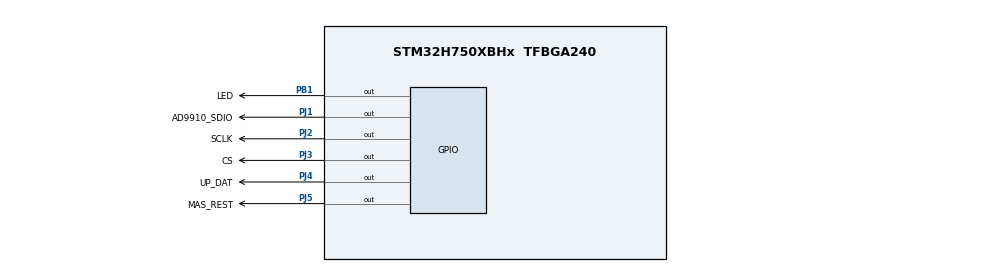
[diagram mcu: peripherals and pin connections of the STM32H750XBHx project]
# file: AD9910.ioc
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Mcu.Family=STM32H7
Mcu.Name=STM32H750XBHx
Mcu.Package=TFBGA240
NVIC.PriorityGroup=NVIC_PRIORITYGROUP_4
PB1.GPIO_Label=LED
PB1.Signal=GPIO_Output
PC14-OSC32_IN\ (OSC32_IN).Mode=LSE-External-Oscillator
PC14-OSC32_IN\ (OSC32_IN).Signal=RCC_OSC32_IN
PC15-OSC32_OUT\ (OSC32_OUT).Mode=LSE-External-Oscillator
PC15-OSC32_OUT\ (OSC32_OUT).Signal=RCC_OSC32_OUT
PH0-OSC_IN\ (PH0).Mode=HSE-External-Oscillator
PH0-OSC_IN\ (PH0).Signal=RCC_OSC_IN
PH1-OSC_OUT\ (PH1).Mode=HSE-External-Oscillator
PH1-OSC_OUT\ (PH1).Signal=RCC_OSC_OUT
PJ1.GPIO_Label=AD9910_SDIO
PJ1.Signal=GPIO_Output
PJ2.GPIO_Label=SCLK
PJ2.Signal=GPIO_Output
PJ3.GPIO_Label=CS
PJ3.Signal=GPIO_Output
PJ4.GPIO_Label=UP_DAT
PJ4.Signal=GPIO_Output
PJ5.GPIO_Label=MAS_REST
PJ5.Signal=GPIO_Output
ProjectManager.HeapSize=0x200
ProjectManager.StackSize=0x400
ProjectManager.TargetToolchain=MDK-ARM V5.32
RCC.ADCFreq_Value=50390625
RCC.APB1Freq_Value=100000000
RCC.APB2Freq_Value=100000000
RCC.APB3Freq_Value=100000000
RCC.APB4Freq_Value=100000000
RCC.CortexFreq_Value=400000000
RCC.D1PPRE=RCC_APB3_DIV2
RCC.D2PPRE1=RCC_APB1_DIV2
RCC.D2PPRE2=RCC_APB2_DIV2
RCC.D3PPRE=RCC_APB4_DIV2
RCC.DIVM1=5
RCC.DIVN1=160
RCC.HCLKFreq_Value=200000000
RCC.HPRE=RCC_HCLK_DIV2
RCC.PLLSourceVirtual=RCC_PLLSOURCE_HSE
RCC.SYSCLKFreq_VALUE=400000000
RCC.SYSCLKSource=RCC_SYSCLKSOURCE_PLLCLK
RCC.USBFreq_Value=400000000
board=custom

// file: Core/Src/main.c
/* USER CODE BEGIN Header */
/**
  ******************************************************************************
  * @file           : main.c
  * @brief          : Main program body
  ******************************************************************************
  * @attention
  *
  * Copyright (c) 2024 STMicroelectronics.
  * All rights reserved.
  *
  * This software is licensed under terms that can be found in the LICENSE file
  * in the root directory of this software component.
  * If no LICENSE file comes with this software, it is provided AS-IS.
  *
  ******************************************************************************
  */
/* USER CODE END Header */
#include "main.h"
#include "gpio.h"
#include "AD9910.h"

void SystemClock_Config(void);
static void MPU_Config(void);

int main(void)
{

  /* MPU Configuration--------------------------------------------------------*/
  MPU_Config();

  /* MCU Configuration--------------------------------------------------------*/

  /* Reset of all peripherals, Initializes the Flash interface and the Systick. */
  HAL_Init();

  /* Configure the system clock */
  SystemClock_Config();

  /* Initialize all configured peripherals */
  MX_GPIO_Init();
  /* USER CODE BEGIN 2 */
  Init_ad9910();
  Freq_convert(100);
  Write_Amplitude(650);//�ɿ����÷�Χ1--650��min--max��
  /* USER CODE END 2 */

  /* Infinite loop */
  /* USER CODE BEGIN WHILE */
  while (1)
  {
	  HAL_GPIO_TogglePin(LED_GPIO_Port,LED_Pin);
	  HAL_Delay(100);
    /* USER CODE END WHILE */

  }
}

void SystemClock_Config(void)
{
  RCC_OscInitTypeDef RCC_OscInitStruct = {0};
  RCC_ClkInitTypeDef RCC_ClkInitStruct = {0};

  /** Supply configuration update enable
  */
  HAL_PWREx_ConfigSupply(PWR_LDO_SUPPLY);

  /** Configure the main internal regulator output voltage
  */
  __HAL_PWR_VOLTAGESCALING_CONFIG(PWR_REGULATOR_VOLTAGE_SCALE1);

  while(!__HAL_PWR_GET_FLAG(PWR_FLAG_VOSRDY)) {}

  /** Initializes the RCC Oscillators according to the specified parameters
  * in the RCC_OscInitTypeDef structure.
  */
  RCC_OscInitStruct.OscillatorType = RCC_OSCILLATORTYPE_HSE;
  RCC_OscInitStruct.HSEState = RCC_HSE_ON;
  RCC_OscInitStruct.PLL.PLLState = RCC_PLL_ON;
  RCC_OscInitStruct.PLL.PLLSource = RCC_PLLSOURCE_HSE;
  RCC_OscInitStruct.PLL.PLLM = 5;
  RCC_OscInitStruct.PLL.PLLN = 160;
  RCC_OscInitStruct.PLL.PLLP = 2;
  RCC_OscInitStruct.PLL.PLLQ = 2;
  RCC_OscInitStruct.PLL.PLLR = 2;
  RCC_OscInitStruct.PLL.PLLRGE = RCC_PLL1VCIRANGE_2;
  RCC_OscInitStruct.PLL.PLLVCOSEL = RCC_PLL1VCOWIDE;
  RCC_OscInitStruct.PLL.PLLFRACN = 0;
  if (HAL_RCC_OscConfig(&RCC_OscInitStruct) != HAL_OK)
  {
    Error_Handler();
  }

  /** Initializes the CPU, AHB and APB buses clocks
  */
  RCC_ClkInitStruct.ClockType = RCC_CLOCKTYPE_HCLK|RCC_CLOCKTYPE_SYSCLK
                              |RCC_CLOCKTYPE_PCLK1|RCC_CLOCKTYPE_PCLK2
                              |RCC_CLOCKTYPE_D3PCLK1|RCC_CLOCKTYPE_D1PCLK1;
  RCC_ClkInitStruct.SYSCLKSource = RCC_SYSCLKSOURCE_PLLCLK;
  RCC_ClkInitStruct.SYSCLKDivider = RCC_SYSCLK_DIV1;
  RCC_ClkInitStruct.AHBCLKDivider = RCC_HCLK_DIV2;
  RCC_ClkInitStruct.APB3CLKDivider = RCC_APB3_DIV2;
  RCC_ClkInitStruct.APB1CLKDivider = RCC_APB1_DIV2;
  RCC_ClkInitStruct.APB2CLKDivider = RCC_APB2_DIV2;
  RCC_ClkInitStruct.APB4CLKDivider = RCC_APB4_DIV2;

  if (HAL_RCC_ClockConfig(&RCC_ClkInitStruct, FLASH_LATENCY_2) != HAL_OK)
  {
    Error_Handler();
  }
}

/* MPU Configuration */

void MPU_Config(void)
{
  MPU_Region_InitTypeDef MPU_InitStruct = {0};

  /* Disables the MPU */
  HAL_MPU_Disable();

  /** Initializes and configures the Region and the memory to be protected
  */
  MPU_InitStruct.Enable = MPU_REGION_ENABLE;
  MPU_InitStruct.Number = MPU_REGION_NUMBER0;
  MPU_InitStruct.BaseAddress = 0x0;
  MPU_InitStruct.Size = MPU_REGION_SIZE_4GB;
  MPU_InitStruct.SubRegionDisable = 0x87;
  MPU_InitStruct.TypeExtField = MPU_TEX_LEVEL0;
  MPU_InitStruct.AccessPermission = MPU_REGION_NO_ACCESS;
  MPU_InitStruct.DisableExec = MPU_INSTRUCTION_ACCESS_DISABLE;
  MPU_InitStruct.IsShareable = MPU_ACCESS_SHAREABLE;
  MPU_InitStruct.IsCacheable = MPU_ACCESS_NOT_CACHEABLE;
  MPU_InitStruct.IsBufferable = MPU_ACCESS_NOT_BUFFERABLE;

  HAL_MPU_ConfigRegion(&MPU_InitStruct);
  /* Enables the MPU */
  HAL_MPU_Enable(MPU_PRIVILEGED_DEFAULT);

}

void Error_Handler(void)
{
  __disable_irq();
  while (1)
  {
  }
}
